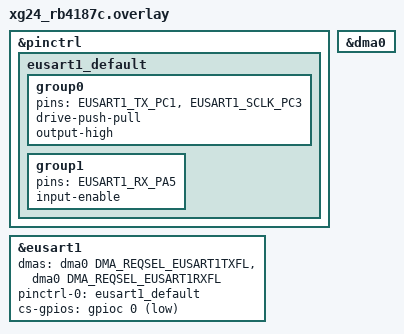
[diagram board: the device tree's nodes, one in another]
/*
 * Copyright (c) 2025 Silicon Laboratories Inc.
 *
 * SPDX-License-Identifier: Apache-2.0
 */

#include <zephyr/dt-bindings/pinctrl/silabs/xg24-pinctrl.h>

&pinctrl {
	eusart1_default: eusart1_default {
		group0 {
			pins = <EUSART1_TX_PC1>, <EUSART1_SCLK_PC3>;
			drive-push-pull;
			output-high;
		};

		group1 {
			pins = <EUSART1_RX_PA5>;
			input-enable;
		};
	};
};

#define SPI_LOOPBACK_FAST_HZ 10000000
#define SPI_LOOPBACK_REG 1

spi_loopback: &eusart1 {
	dmas = <&dma0 DMA_REQSEL_EUSART1TXFL>,
	       <&dma0 DMA_REQSEL_EUSART1RXFL>;
	dma-names = "tx", "rx";
	#address-cells = <1>;
	#size-cells = <0>;
	pinctrl-0 = <&eusart1_default>;
	pinctrl-names = "default";
	status = "okay";
	cs-gpios = <&gpioc 0 GPIO_ACTIVE_LOW>;
};

&dma0 {
	status = "okay";
};

#include "../spi-loopback.dtsi"
